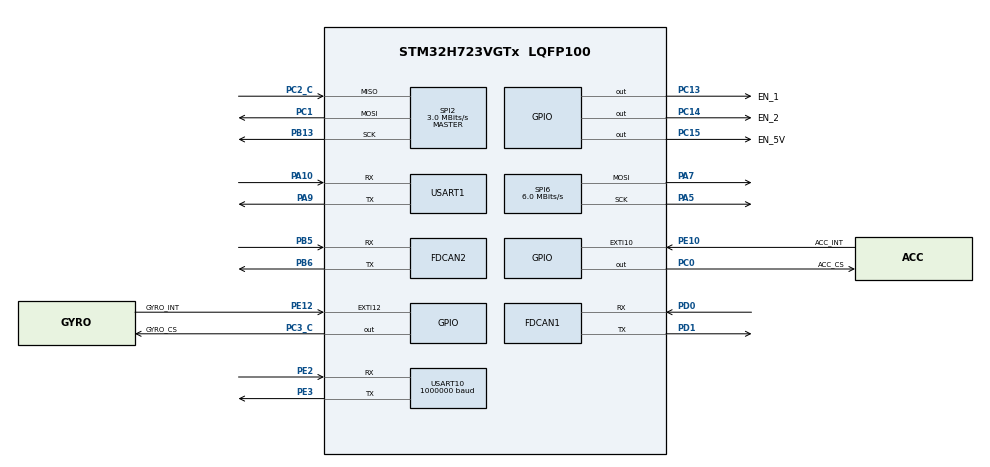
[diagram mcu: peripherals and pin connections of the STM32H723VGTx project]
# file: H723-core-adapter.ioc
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Dma.Request0=SPI2_RX
Dma.Request1=SPI2_TX
Dma.Request2=USART10_RX
Dma.Request3=USART1_RX
Dma.Request4=USART1_TX
Dma.SPI2_RX.0.Direction=DMA_PERIPH_TO_MEMORY
Dma.SPI2_RX.0.EventEnable=DISABLE
Dma.SPI2_RX.0.FIFOMode=DMA_FIFOMODE_DISABLE
Dma.SPI2_RX.0.Instance=DMA1_Stream0
Dma.SPI2_RX.0.MemDataAlignment=DMA_MDATAALIGN_BYTE
Dma.SPI2_RX.0.MemInc=DMA_MINC_ENABLE
Dma.SPI2_RX.0.Mode=DMA_NORMAL
Dma.SPI2_RX.0.PeriphDataAlignment=DMA_PDATAALIGN_BYTE
Dma.SPI2_RX.0.PeriphInc=DMA_PINC_DISABLE
Dma.SPI2_RX.0.Polarity=HAL_DMAMUX_REQ_GEN_RISING
Dma.SPI2_RX.0.Priority=DMA_PRIORITY_VERY_HIGH
Dma.SPI2_RX.0.RequestNumber=1
Dma.SPI2_RX.0.SignalID=NONE
Dma.SPI2_RX.0.SyncEnable=DISABLE
Dma.SPI2_RX.0.SyncPolarity=HAL_DMAMUX_SYNC_NO_EVENT
Dma.SPI2_RX.0.SyncRequestNumber=1
Dma.SPI2_RX.0.SyncSignalID=NONE
Dma.SPI2_TX.1.Direction=DMA_MEMORY_TO_PERIPH
Dma.SPI2_TX.1.EventEnable=DISABLE
Dma.SPI2_TX.1.FIFOMode=DMA_FIFOMODE_DISABLE
Dma.SPI2_TX.1.Instance=DMA1_Stream1
Dma.SPI2_TX.1.MemDataAlignment=DMA_MDATAALIGN_BYTE
Dma.SPI2_TX.1.MemInc=DMA_MINC_ENABLE
Dma.SPI2_TX.1.Mode=DMA_NORMAL
Dma.SPI2_TX.1.PeriphDataAlignment=DMA_PDATAALIGN_BYTE
Dma.SPI2_TX.1.PeriphInc=DMA_PINC_DISABLE
Dma.SPI2_TX.1.Polarity=HAL_DMAMUX_REQ_GEN_RISING
Dma.SPI2_TX.1.Priority=DMA_PRIORITY_HIGH
Dma.SPI2_TX.1.RequestNumber=1
Dma.SPI2_TX.1.SignalID=NONE
Dma.SPI2_TX.1.SyncEnable=DISABLE
Dma.SPI2_TX.1.SyncPolarity=HAL_DMAMUX_SYNC_NO_EVENT
Dma.SPI2_TX.1.SyncRequestNumber=1
Dma.SPI2_TX.1.SyncSignalID=NONE
Dma.USART10_RX.2.Direction=DMA_PERIPH_TO_MEMORY
Dma.USART10_RX.2.EventEnable=DISABLE
Dma.USART10_RX.2.FIFOMode=DMA_FIFOMODE_DISABLE
Dma.USART10_RX.2.Instance=DMA1_Stream2
Dma.USART10_RX.2.MemDataAlignment=DMA_MDATAALIGN_BYTE
Dma.USART10_RX.2.MemInc=DMA_MINC_ENABLE
Dma.USART10_RX.2.Mode=DMA_NORMAL
Dma.USART10_RX.2.PeriphDataAlignment=DMA_PDATAALIGN_BYTE
Dma.USART10_RX.2.PeriphInc=DMA_PINC_DISABLE
Dma.USART10_RX.2.Polarity=HAL_DMAMUX_REQ_GEN_RISING
Dma.USART10_RX.2.Priority=DMA_PRIORITY_LOW
Dma.USART10_RX.2.RequestNumber=1
Dma.USART10_RX.2.SignalID=NONE
Dma.USART10_RX.2.SyncEnable=DISABLE
Dma.USART10_RX.2.SyncPolarity=HAL_DMAMUX_SYNC_NO_EVENT
Dma.USART10_RX.2.SyncRequestNumber=1
Dma.USART10_RX.2.SyncSignalID=NONE
Dma.USART1_RX.3.Direction=DMA_PERIPH_TO_MEMORY
Dma.USART1_RX.3.EventEnable=DISABLE
Dma.USART1_RX.3.FIFOMode=DMA_FIFOMODE_DISABLE
Dma.USART1_RX.3.Instance=DMA1_Stream3
Dma.USART1_RX.3.MemDataAlignment=DMA_MDATAALIGN_BYTE
Dma.USART1_RX.3.MemInc=DMA_MINC_ENABLE
Dma.USART1_RX.3.Mode=DMA_NORMAL
Dma.USART1_RX.3.PeriphDataAlignment=DMA_PDATAALIGN_BYTE
Dma.USART1_RX.3.PeriphInc=DMA_PINC_DISABLE
Dma.USART1_RX.3.Polarity=HAL_DMAMUX_REQ_GEN_RISING
Dma.USART1_RX.3.Priority=DMA_PRIORITY_LOW
Dma.USART1_RX.3.RequestNumber=1
Dma.USART1_RX.3.SignalID=NONE
Dma.USART1_RX.3.SyncEnable=DISABLE
Dma.USART1_RX.3.SyncPolarity=HAL_DMAMUX_SYNC_NO_EVENT
Dma.USART1_RX.3.SyncRequestNumber=1
Dma.USART1_RX.3.SyncSignalID=NONE
Dma.USART1_TX.4.Direction=DMA_MEMORY_TO_PERIPH
Dma.USART1_TX.4.EventEnable=DISABLE
Dma.USART1_TX.4.FIFOMode=DMA_FIFOMODE_DISABLE
Dma.USART1_TX.4.Instance=DMA1_Stream4
Dma.USART1_TX.4.MemDataAlignment=DMA_MDATAALIGN_BYTE
Dma.USART1_TX.4.MemInc=DMA_MINC_ENABLE
Dma.USART1_TX.4.Mode=DMA_NORMAL
Dma.USART1_TX.4.PeriphDataAlignment=DMA_PDATAALIGN_BYTE
Dma.USART1_TX.4.PeriphInc=DMA_PINC_DISABLE
Dma.USART1_TX.4.Polarity=HAL_DMAMUX_REQ_GEN_RISING
Dma.USART1_TX.4.Priority=DMA_PRIORITY_LOW
Dma.USART1_TX.4.RequestNumber=1
Dma.USART1_TX.4.SignalID=NONE
Dma.USART1_TX.4.SyncEnable=DISABLE
Dma.USART1_TX.4.SyncPolarity=HAL_DMAMUX_SYNC_NO_EVENT
Dma.USART1_TX.4.SyncRequestNumber=1
Dma.USART1_TX.4.SyncSignalID=NONE
FDCAN1.AutoRetransmission=DISABLE
FDCAN1.CalculateBaudRateNominal=1000000
FDCAN1.CalculateTimeBitNominal=1000
FDCAN1.CalculateTimeQuantumNominal=62.5
FDCAN1.DataPrescaler=6
FDCAN1.DataSyncJumpWidth=2
FDCAN1.DataTimeSeg1=13
FDCAN1.DataTimeSeg2=2
FDCAN1.ExtFiltersNbr=4
FDCAN1.Mode=FDCAN_MODE_NORMAL
FDCAN1.NominalPrescaler=6
FDCAN1.NominalSyncJumpWidth=2
FDCAN1.NominalTimeSeg1=13
FDCAN1.NominalTimeSeg2=2
FDCAN1.ProtocolException=ENABLE
FDCAN1.RxBuffersNbr=2
FDCAN1.RxFifo0ElmtsNbr=8
FDCAN1.RxFifo1ElmtsNbr=8
FDCAN1.StdFiltersNbr=4
FDCAN1.TxBuffersNbr=8
FDCAN1.TxEventsNbr=8
FDCAN1.TxFifoQueueElmtsNbr=8
FDCAN2.AutoRetransmission=DISABLE
FDCAN2.CalculateBaudRateNominal=1000000
FDCAN2.CalculateTimeBitNominal=1000
FDCAN2.CalculateTimeQuantumNominal=62.5
FDCAN2.DataPrescaler=6
FDCAN2.DataSyncJumpWidth=2
FDCAN2.DataTimeSeg1=13
FDCAN2.DataTimeSeg2=2
FDCAN2.ExtFiltersNbr=4
FDCAN2.NominalPrescaler=6
FDCAN2.NominalSyncJumpWidth=2
FDCAN2.NominalTimeSeg1=13
FDCAN2.NominalTimeSeg2=2
FDCAN2.ProtocolException=ENABLE
FDCAN2.RxBuffersNbr=2
FDCAN2.RxFifo0ElmtsNbr=8
FDCAN2.RxFifo1ElmtsNbr=8
FDCAN2.StdFiltersNbr=4
FDCAN2.TxBuffersNbr=8
FDCAN2.TxEventsNbr=8
FDCAN2.TxFifoQueueElmtsNbr=8
Mcu.Family=STM32H7
Mcu.Name=STM32H723VGTx
Mcu.Package=LQFP100
NVIC.DMA1_Stream0_IRQn=true\:1\:0\:true\:false\:true\:false\:true\:true
NVIC.DMA1_Stream1_IRQn=true\:2\:0\:true\:false\:true\:false\:true\:true
NVIC.DMA1_Stream2_IRQn=true\:0\:0\:false\:false\:true\:false\:true\:true
NVIC.DMA1_Stream3_IRQn=true\:0\:0\:false\:false\:true\:false\:true\:true
NVIC.DMA1_Stream4_IRQn=true\:0\:0\:false\:false\:true\:false\:true\:true
NVIC.FDCAN1_IT0_IRQn=true\:0\:0\:false\:false\:true\:true\:true\:true
NVIC.FDCAN1_IT1_IRQn=true\:0\:0\:false\:false\:true\:true\:true\:true
NVIC.FDCAN2_IT0_IRQn=true\:0\:0\:false\:false\:true\:true\:true\:true
NVIC.FDCAN2_IT1_IRQn=true\:0\:0\:false\:false\:true\:true\:true\:true
NVIC.PriorityGroup=NVIC_PRIORITYGROUP_4
NVIC.SPI2_IRQn=true\:5\:0\:true\:false\:true\:false\:true\:true
NVIC.TIM2_IRQn=true\:0\:0\:false\:false\:true\:true\:true\:true
NVIC.USART10_IRQn=true\:0\:0\:false\:false\:true\:true\:true\:true
NVIC.USART1_IRQn=true\:0\:0\:false\:false\:true\:true\:true\:true
PA10.Mode=Asynchronous
PA10.Signal=USART1_RX
PA13(JTMS/SWDIO).Mode=Serial_Wire
PA13(JTMS/SWDIO).Signal=DEBUG_JTMS-SWDIO
PA14(JTCK/SWCLK).Mode=Serial_Wire
PA14(JTCK/SWCLK).Signal=DEBUG_JTCK-SWCLK
PA5.GPIO_Speed=GPIO_SPEED_FREQ_VERY_HIGH
PA5.Mode=TX_Only_Simplex_Unidirect_Master
PA5.Signal=SPI6_SCK
PA7.GPIO_Speed=GPIO_SPEED_FREQ_VERY_HIGH
PA7.Mode=TX_Only_Simplex_Unidirect_Master
PA7.Signal=SPI6_MOSI
PA9.Mode=Asynchronous
PA9.Signal=USART1_TX
PB13.GPIO_Speed=GPIO_SPEED_FREQ_VERY_HIGH
PB13.Mode=Full_Duplex_Master
PB13.Signal=SPI2_SCK
PB5.Mode=FDCAN_Activate
PB5.Signal=FDCAN2_RX
PB6.GPIO_FM6=SYSCFG_PMCR_I2C_PB6_FMP
PB6.Mode=FDCAN_Activate
PB6.Signal=FDCAN2_TX
PC0.GPIO_Label=ACC_CS
PC0.GPIO_Speed=GPIO_SPEED_FREQ_VERY_HIGH
PC0.PinState=GPIO_PIN_SET
PC0.Signal=GPIO_Output
PC1.GPIO_Speed=GPIO_SPEED_FREQ_VERY_HIGH
PC1.Mode=Full_Duplex_Master
PC1.Signal=SPI2_MOSI
PC13.GPIO_Label=EN_1
PC13.Signal=GPIO_Output
PC14-OSC32_IN.GPIO_Label=EN_2
PC14-OSC32_IN.Signal=GPIO_Output
PC15-OSC32_OUT.GPIO_Label=EN_5V
PC15-OSC32_OUT.Signal=GPIO_Output
PC2_C.GPIO_Speed=GPIO_SPEED_FREQ_VERY_HIGH
PC2_C.Mode=Full_Duplex_Master
PC2_C.Signal=SPI2_MISO
PC3_C.GPIO_Label=GYRO_CS
PC3_C.GPIO_Speed=GPIO_SPEED_FREQ_VERY_HIGH
PC3_C.PinState=GPIO_PIN_SET
PC3_C.Signal=GPIO_Output
PD0.Mode=FDCAN_Activate
PD0.Signal=FDCAN1_RX
PD1.Mode=FDCAN_Activate
PD1.Signal=FDCAN1_TX
PE10.GPIO_Label=ACC_INT
PE10.Signal=GPXTI10
PE12.GPIO_Label=GYRO_INT
PE12.Signal=GPXTI12
PE2.Mode=Asynchronous
PE2.Signal=USART10_RX
PE3.Mode=Asynchronous
PE3.Signal=USART10_TX
PH0-OSC_IN.Mode=HSE-External-Oscillator
PH0-OSC_IN.Signal=RCC_OSC_IN
PH1-OSC_OUT.Mode=HSE-External-Oscillator
PH1-OSC_OUT.Signal=RCC_OSC_OUT
ProjectManager.HeapSize=0x200
ProjectManager.StackSize=0x800
ProjectManager.TargetToolchain=STM32CubeIDE
RCC.ADCFreq_Value=48375000
RCC.APB1Freq_Value=96000000
RCC.APB2Freq_Value=96000000
RCC.APB3Freq_Value=96000000
RCC.APB4Freq_Value=96000000
RCC.CortexFreq_Value=192000000
RCC.D1PPRE=RCC_APB3_DIV2
RCC.D2PPRE1=RCC_APB1_DIV2
RCC.D2PPRE2=RCC_APB2_DIV2
RCC.D3PPRE=RCC_APB4_DIV2
RCC.DIVM1=2
RCC.DIVN1=16
RCC.DIVP1=1
RCC.HCLKFreq_Value=192000000
RCC.HSE_VALUE=24000000
RCC.PLL2FRACN=0
RCC.PLL3FRACN=0
RCC.PLLFRACN=0
RCC.PLLSourceVirtual=RCC_PLLSOURCE_HSE
RCC.SPI6CLockSelection=RCC_SPI6CLKSOURCE_HSE
RCC.SYSCLKFreq_VALUE=192000000
RCC.SYSCLKSource=RCC_SYSCLKSOURCE_PLLCLK
RCC.USBFreq_Value=96000000
SPI2.BaudRatePrescaler=SPI_BAUDRATEPRESCALER_32
SPI2.CLKPhase=SPI_PHASE_2EDGE
SPI2.CLKPolarity=SPI_POLARITY_HIGH
SPI2.CalculateBaudRate=3.0 MBits/s
SPI2.DataSize=SPI_DATASIZE_8BIT
SPI2.Direction=SPI_DIRECTION_2LINES
SPI2.Mode=SPI_MODE_MASTER
SPI2.VirtualType=VM_MASTER
SPI6.BaudRatePrescaler=SPI_BAUDRATEPRESCALER_4
SPI6.CLKPhase=SPI_PHASE_2EDGE
SPI6.CalculateBaudRate=6.0 MBits/s
SPI6.DataSize=SPI_DATASIZE_8BIT
SPI6.Direction=SPI_DIRECTION_2LINES_TXONLY
SPI6.Mode=SPI_MODE_MASTER
SPI6.VirtualType=VM_MASTER
TIM2.Period=999
TIM2.Prescaler=239
USART1.VirtualMode-Asynchronous=VM_ASYNC
USART10.BaudRate=1000000
USART10.VirtualMode=VM_ASYNC
VP_MEMORYMAP_VS_MEMORYMAP.Mode=CurAppReg
VP_TIM2_VS_ClockSourceINT.Mode=Internal
board=custom

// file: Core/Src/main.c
/* USER CODE BEGIN Header */
/**
  ******************************************************************************
  * @file           : main.c
  * @brief          : Three-joint duck-leg outer-PD POC application entry point.
  ******************************************************************************
  */
/* USER CODE END Header */
#include "main.h"
#include "dma.h"
#include "fdcan.h"
#include "spi.h"
#include "tim.h"
#include "usart.h"
#include "gpio.h"

/* USER CODE BEGIN Includes */
#include "leg_pd_poc.h"
/* USER CODE END Includes */

/* USER CODE BEGIN PV */
/* TIM2 IRQ releases one deterministic foreground 1 kHz controller iteration. */
volatile uint8_t loop_1khz_flag = 0U;
/* USER CODE END PV */

void SystemClock_Config(void);

int main(void)
{

  /* MCU Configuration--------------------------------------------------------*/
  HAL_Init();

  SystemClock_Config();

  MX_GPIO_Init();
  MX_DMA_Init();
  MX_SPI2_Init();
  MX_USART1_UART_Init();
  MX_TIM2_Init();
  MX_FDCAN1_Init();
  MX_FDCAN2_Init();
  MX_USART10_UART_Init();
  MX_SPI6_Init();

  /* USER CODE BEGIN 2 */
  /* Starts CAN RX, PC/G030 UART RX DMA, controlled 5 V, and BMI088. */
  LegPdPoc_Init();

  /* TIM2 must be configured in CubeMX for a real 1 kHz update interrupt. */
  if (HAL_TIM_Base_Start_IT(&htim2) != HAL_OK)
  {
    Error_Handler();
  }
  /* USER CODE END 2 */

  /* Infinite loop */
  while (1)
  {

    /* USER CODE BEGIN 3 */
    /* Non-blocking PC telemetry and WS2812 status service. */
    LegPdPoc_Service();

    if (loop_1khz_flag != 0U)
    {
      loop_1khz_flag = 0U;
      /* G030 state, BMI088 sample, safety checks, and outer torque PD. */
      LegPdPoc_Control1kHz();
    }
    /* USER CODE END 3 */
  }
  /* USER CODE END WHILE */
}

void SystemClock_Config(void)
{
  RCC_OscInitTypeDef RCC_OscInitStruct = {0};
  RCC_ClkInitTypeDef RCC_ClkInitStruct = {0};

  HAL_PWREx_ConfigSupply(PWR_LDO_SUPPLY);
  __HAL_PWR_VOLTAGESCALING_CONFIG(PWR_REGULATOR_VOLTAGE_SCALE1);
  while(!__HAL_PWR_GET_FLAG(PWR_FLAG_VOSRDY)) {}

  RCC_OscInitStruct.OscillatorType = RCC_OSCILLATORTYPE_HSE;
  RCC_OscInitStruct.HSEState = RCC_HSE_ON;
  RCC_OscInitStruct.PLL.PLLState = RCC_PLL_ON;
  RCC_OscInitStruct.PLL.PLLSource = RCC_PLLSOURCE_HSE;
  RCC_OscInitStruct.PLL.PLLM = 2;
  RCC_OscInitStruct.PLL.PLLN = 16;
  RCC_OscInitStruct.PLL.PLLP = 1;
  RCC_OscInitStruct.PLL.PLLQ = 2;
  RCC_OscInitStruct.PLL.PLLR = 2;
  RCC_OscInitStruct.PLL.PLLRGE = RCC_PLL1VCIRANGE_3;
  RCC_OscInitStruct.PLL.PLLVCOSEL = RCC_PLL1VCOWIDE;
  RCC_OscInitStruct.PLL.PLLFRACN = 0;
  if (HAL_RCC_OscConfig(&RCC_OscInitStruct) != HAL_OK)
  {
    Error_Handler();
  }

  RCC_ClkInitStruct.ClockType = RCC_CLOCKTYPE_HCLK|RCC_CLOCKTYPE_SYSCLK
                              | RCC_CLOCKTYPE_PCLK1|RCC_CLOCKTYPE_PCLK2
                              | RCC_CLOCKTYPE_D3PCLK1|RCC_CLOCKTYPE_D1PCLK1;
  RCC_ClkInitStruct.SYSCLKSource = RCC_SYSCLKSOURCE_PLLCLK;
  RCC_ClkInitStruct.SYSCLKDivider = RCC_SYSCLK_DIV1;
  RCC_ClkInitStruct.AHBCLKDivider = RCC_HCLK_DIV1;
  RCC_ClkInitStruct.APB3CLKDivider = RCC_APB3_DIV2;
  RCC_ClkInitStruct.APB1CLKDivider = RCC_APB1_DIV2;
  RCC_ClkInitStruct.APB2CLKDivider = RCC_APB2_DIV2;
  RCC_ClkInitStruct.APB4CLKDivider = RCC_APB4_DIV2;
  if (HAL_RCC_ClockConfig(&RCC_ClkInitStruct, FLASH_LATENCY_2) != HAL_OK)
  {
    Error_Handler();
  }
}

/* USER CODE BEGIN 4 */
void HAL_TIM_PeriodElapsedCallback(TIM_HandleTypeDef *htim)
{
  if (htim->Instance == TIM2)
  {
    loop_1khz_flag = 1U;
  }
}
/* USER CODE END 4 */

void Error_Handler(void)
{
  __disable_irq();
  while (1)
  {
  }
}

#ifdef USE_FULL_ASSERT
void assert_failed(uint8_t *file, uint32_t line)
{
  /* USER CODE BEGIN 6 */
  (void)file;
  (void)line;
  /* USER CODE END 6 */
}
#endif /* USE_FULL_ASSERT */
